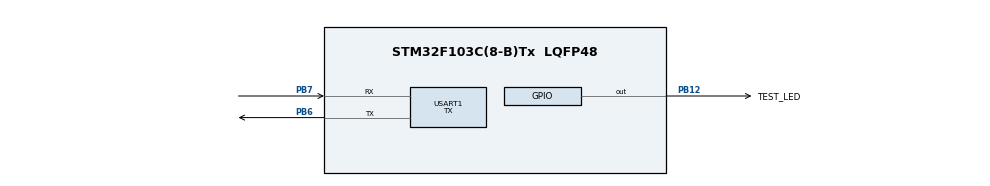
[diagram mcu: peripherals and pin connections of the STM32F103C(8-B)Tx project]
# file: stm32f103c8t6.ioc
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FREERTOS.INCLUDE_eTaskGetState=1
FREERTOS.INCLUDE_uxTaskGetStackHighWaterMark=1
FREERTOS.INCLUDE_vTaskDelayUntil=1
FREERTOS.INCLUDE_xEventGroupSetBitFromISR=1
FREERTOS.INCLUDE_xQueueGetMutexHolder=0
FREERTOS.INCLUDE_xSemaphoreGetMutexHolder=1
FREERTOS.INCLUDE_xTaskGetSchedulerState=1
FREERTOS.INCLUDE_xTaskResumeFromISR=1
FREERTOS.INCLUDE_xTimerPendFunctionCall=1
FREERTOS.Tasks01=defaultTask,3,1024,osStartDefaultTask,Default,NULL,Static,defaultTaskBuffer,defaultTaskControlBlock
FREERTOS.configENABLE_BACKWARD_COMPATIBILITY=0
FREERTOS.configUSE_NEWLIB_REENTRANT=1
FREERTOS.configUSE_RECURSIVE_MUTEXES=1
FREERTOS.configUSE_TASK_NOTIFICATIONS=1
FREERTOS.configUSE_TRACE_FACILITY=0
FREERTOS.copyHeapFile=0
Mcu.Family=STM32F1
Mcu.Name=STM32F103C(8-B)Tx
Mcu.Package=LQFP48
NVIC.PriorityGroup=NVIC_PRIORITYGROUP_4
PA13.Mode=Serial_Wire
PA13.Signal=SYS_JTMS-SWDIO
PA14.Mode=Serial_Wire
PA14.Signal=SYS_JTCK-SWCLK
PB12.GPIO_Label=TEST_LED
PB12.GPIO_PuPd=GPIO_NOPULL
PB12.Signal=GPIO_Output
PB6.Mode=Asynchronous
PB6.Signal=USART1_TX
PB7.Mode=Asynchronous
PB7.Signal=USART1_RX
PD0-OSC_IN.Mode=HSE-External-Oscillator
PD0-OSC_IN.Signal=RCC_OSC_IN
PD1-OSC_OUT.Mode=HSE-External-Oscillator
PD1-OSC_OUT.Signal=RCC_OSC_OUT
ProjectManager.HeapSize=0x200
ProjectManager.StackSize=0x400
ProjectManager.TargetToolchain=CMake
RCC.AHBFreq_Value=52000000
RCC.APB1CLKDivider=RCC_HCLK_DIV2
RCC.APB1Freq_Value=26000000
RCC.APB1TimFreq_Value=52000000
RCC.APB2Freq_Value=52000000
RCC.APB2TimFreq_Value=52000000
RCC.HCLKFreq_Value=52000000
RCC.HSEDivPLL=RCC_HSE_PREDIV_DIV2
RCC.PLLMUL=RCC_PLL_MUL13
RCC.PLLSourceVirtual=RCC_PLLSOURCE_HSE
RCC.SYSCLKFreq_VALUE=52000000
RCC.SYSCLKSource=RCC_SYSCLKSOURCE_PLLCLK
RCC.USBFreq_Value=52000000
STMicroelectronics.X-CUBE-ALGOBUILD.1.4.0.LibraryCcDSPOoLibraryJjDSPOoLibrary=true
USART1.Mode=MODE_TX
USART1.VirtualMode=VM_ASYNC
VP_FREERTOS_VS_CMSIS_V1.Mode=CMSIS_V1
VP_STMicroelectronics.X-CUBE-ALGOBUILD_VS_DSPOoLibraryJjLibrary_1.4.0_1.4.0.Mode=DSPOoLibraryJjLibrary
board=custom

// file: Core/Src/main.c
/* USER CODE BEGIN Header */
/**
  ******************************************************************************
  * @file           : main.c
  * @brief          : Main program body
  ******************************************************************************
  * @attention
  *
  * Copyright (c) 2025 STMicroelectronics.
  * All rights reserved.
  *
  * This software is licensed under terms that can be found in the LICENSE file
  * in the root directory of this software component.
  * If no LICENSE file comes with this software, it is provided AS-IS.
  *
  ******************************************************************************
  */
/* USER CODE END Header */
#include "main.h"
#include "cmsis_os.h"
#include "usart.h"
#include "gpio.h"

void SystemClock_Config(void);
void MX_FREERTOS_Init(void);

int main(void)
{

  /* MCU Configuration--------------------------------------------------------*/

  /* Reset of all peripherals, Initializes the Flash interface and the Systick. */
  LL_APB2_GRP1_EnableClock(LL_APB2_GRP1_PERIPH_AFIO);
  LL_APB1_GRP1_EnableClock(LL_APB1_GRP1_PERIPH_PWR);

  /* System interrupt init*/
  NVIC_SetPriorityGrouping(NVIC_PRIORITYGROUP_4);

  /* PendSV_IRQn interrupt configuration */
  NVIC_SetPriority(PendSV_IRQn, NVIC_EncodePriority(NVIC_GetPriorityGrouping(),15, 0));
  /* SysTick_IRQn interrupt configuration */
  NVIC_SetPriority(SysTick_IRQn, NVIC_EncodePriority(NVIC_GetPriorityGrouping(),15, 0));

  /** NOJTAG: JTAG-DP Disabled and SW-DP Enabled
  */
  LL_GPIO_AF_Remap_SWJ_NOJTAG();

  /* Configure the system clock */
  SystemClock_Config();

  /* Initialize all configured peripherals */
  MX_GPIO_Init();
  MX_USART1_UART_Init();

  /* Call init function for freertos objects (in cmsis_os2.c) */
  MX_FREERTOS_Init();

  /* Start scheduler */
  osKernelStart();

  /* We should never get here as control is now taken by the scheduler */

  /* Infinite loop */
  while (1)
  {

  }
}

void SystemClock_Config(void)
{
  LL_FLASH_SetLatency(LL_FLASH_LATENCY_2);
  while(LL_FLASH_GetLatency()!= LL_FLASH_LATENCY_2)
  {
  }
  LL_RCC_HSE_Enable();

   /* Wait till HSE is ready */
  while(LL_RCC_HSE_IsReady() != 1)
  {

  }
  LL_RCC_PLL_ConfigDomain_SYS(LL_RCC_PLLSOURCE_HSE_DIV_2, LL_RCC_PLL_MUL_13);
  LL_RCC_PLL_Enable();

   /* Wait till PLL is ready */
  while(LL_RCC_PLL_IsReady() != 1)
  {

  }
  LL_RCC_SetAHBPrescaler(LL_RCC_SYSCLK_DIV_1);
  LL_RCC_SetAPB1Prescaler(LL_RCC_APB1_DIV_2);
  LL_RCC_SetAPB2Prescaler(LL_RCC_APB2_DIV_1);
  LL_RCC_SetSysClkSource(LL_RCC_SYS_CLKSOURCE_PLL);

   /* Wait till System clock is ready */
  while(LL_RCC_GetSysClkSource() != LL_RCC_SYS_CLKSOURCE_STATUS_PLL)
  {

  }
  LL_Init1msTick(52000000);
  LL_SetSystemCoreClock(52000000);
}

void Error_Handler(void)
{
  __disable_irq();
  while (1)
  {
  }
}

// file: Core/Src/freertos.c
/* USER CODE BEGIN Header */
/**
  ******************************************************************************
  * File Name          : freertos.c
  * Description        : Code for freertos applications
  ******************************************************************************
  * @attention
  *
  * Copyright (c) 2025 STMicroelectronics.
  * All rights reserved.
  *
  * This software is licensed under terms that can be found in the LICENSE file
  * in the root directory of this software component.
  * If no LICENSE file comes with this software, it is provided AS-IS.
  *
  ******************************************************************************
  */
/* USER CODE END Header */

#include "FreeRTOS.h"
#include "task.h"
#include "main.h"
#include "cmsis_os.h"

/* USER CODE BEGIN Includes */

#include "emdevif/attributes_and_useful_macros.h"
#include "stm32_ll_test_func_impl.h"

/* USER CODE END Includes */

osThreadId defaultTaskHandle;
uint32_t defaultTaskBuffer[ 1024 ];
osStaticThreadDef_t defaultTaskControlBlock;

void osStartDefaultTask(void const * argument);

void MX_FREERTOS_Init(void); /* (MISRA C 2004 rule 8.1) */

/* GetIdleTaskMemory prototype (linked to static allocation support) */
void vApplicationGetIdleTaskMemory( StaticTask_t **ppxIdleTaskTCBBuffer, StackType_t **ppxIdleTaskStackBuffer, uint32_t *pulIdleTaskStackSize );

/* GetTimerTaskMemory prototype (linked to static allocation support) */
void vApplicationGetTimerTaskMemory( StaticTask_t **ppxTimerTaskTCBBuffer, StackType_t **ppxTimerTaskStackBuffer, uint32_t *pulTimerTaskStackSize );

/* USER CODE BEGIN GET_IDLE_TASK_MEMORY */
static StaticTask_t xIdleTaskTCBBuffer;
static StackType_t xIdleStack[configMINIMAL_STACK_SIZE];

void vApplicationGetIdleTaskMemory( StaticTask_t **ppxIdleTaskTCBBuffer, StackType_t **ppxIdleTaskStackBuffer, uint32_t *pulIdleTaskStackSize )
{
  *ppxIdleTaskTCBBuffer = &xIdleTaskTCBBuffer;
  *ppxIdleTaskStackBuffer = &xIdleStack[0];
  *pulIdleTaskStackSize = configMINIMAL_STACK_SIZE;
  /* place for user code */
}
/* USER CODE END GET_IDLE_TASK_MEMORY */

/* USER CODE BEGIN GET_TIMER_TASK_MEMORY */
static StaticTask_t xTimerTaskTCBBuffer;
static StackType_t xTimerStack[configTIMER_TASK_STACK_DEPTH];

void vApplicationGetTimerTaskMemory( StaticTask_t **ppxTimerTaskTCBBuffer, StackType_t **ppxTimerTaskStackBuffer, uint32_t *pulTimerTaskStackSize )
{
  *ppxTimerTaskTCBBuffer = &xTimerTaskTCBBuffer;
  *ppxTimerTaskStackBuffer = &xTimerStack[0];
  *pulTimerTaskStackSize = configTIMER_TASK_STACK_DEPTH;
  /* place for user code */
}
/* USER CODE END GET_TIMER_TASK_MEMORY */

void MX_FREERTOS_Init(void) {

  /* Create the thread(s) */
  /* definition and creation of defaultTask */
  osThreadStaticDef(defaultTask, osStartDefaultTask, osPriorityRealtime, 0, 1024, defaultTaskBuffer, &defaultTaskControlBlock);
  defaultTaskHandle = osThreadCreate(osThread(defaultTask), NULL);

}

/* USER CODE BEGIN Header_osStartDefaultTask */
/**
  * @brief  Function implementing the defaultTask thread.
  * @param  argument: Not used
  * @retval None
  */
EMDEVIF_NO_RETURN
/* USER CODE END Header_osStartDefaultTask */
void osStartDefaultTask(void const * argument)
{
  /* USER CODE BEGIN osStartDefaultTask */

  EMDEVIF_UNUSED(argument);

  testInit(USART1);
  testEntry();

  /* Infinite loop */
  for(;;)
  {
    osDelay(1);
  }
  /* USER CODE END osStartDefaultTask */
}
